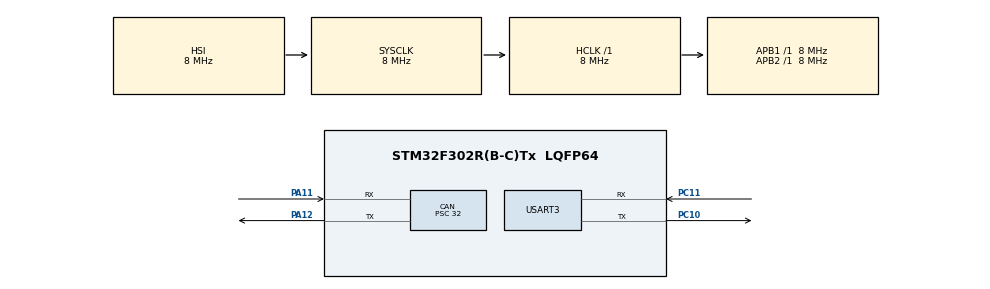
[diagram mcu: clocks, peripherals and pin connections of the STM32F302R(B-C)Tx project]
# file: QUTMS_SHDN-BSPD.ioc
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CAN.CalculateTimeQuantum=4000.0
CAN.Prescaler=32
Mcu.Family=STM32F3
Mcu.Name=STM32F302R(B-C)Tx
Mcu.Package=LQFP64
NVIC.PriorityGroup=NVIC_PRIORITYGROUP_4
PA11.Mode=Master
PA11.Signal=CAN_RX
PA12.Mode=Master
PA12.Signal=CAN_TX
PC10.Mode=Asynchronous
PC10.Signal=USART3_TX
PC11.Mode=Asynchronous
PC11.Signal=USART3_RX
ProjectManager.HeapSize=0x200
ProjectManager.StackSize=0x400
ProjectManager.TargetToolchain=STM32CubeIDE
RCC.AHBFreq_Value=8000000
RCC.APB1Freq_Value=8000000
RCC.APB2Freq_Value=8000000
RCC.CortexFreq_Value=8000000
RCC.HSE_VALUE=8000000
RCC.HSI_VALUE=8000000
RCC.LSE_VALUE=32768
RCC.SYSCLKFreq_VALUE=8000000
USART3.VirtualMode-Asynchronous=VM_ASYNC
board=custom

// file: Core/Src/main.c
/* USER CODE BEGIN Header */
/**
  ******************************************************************************
  * @file           : main.c
  * @brief          : Main program body
  ******************************************************************************
  * @attention
  *
  * <h2><center>&copy; Copyright (c) 2020 STMicroelectronics.
  * All rights reserved.</center></h2>
  *
  * This software component is licensed by ST under BSD 3-Clause license,
  * the "License"; You may not use this file except in compliance with the
  * License. You may obtain a copy of the License at:
  *                        opensource.org/licenses/BSD-3-Clause
  *
  ******************************************************************************
  */
/* USER CODE END Header */
#include "main.h"
#include "can.h"
#include "usart.h"
#include "gpio.h"

/* USER CODE BEGIN PV */
CAN_TxHeaderTypeDef TxHeader;

uint8_t TxData[8];
uint32_t TxMailbox;
/* USER CODE END PV */

void SystemClock_Config(void);

int main(void)
{
  /* USER CODE BEGIN 1 */
	char msg[256];

	TxHeader.ExtId = 0x02;
	TxHeader.IDE = CAN_ID_EXT;
	TxHeader.RTR = CAN_RTR_DATA;
	TxHeader.DLC = 2;
	TxHeader.TransmitGlobalTime = DISABLE;
  /* USER CODE END 1 */

  /* MCU Configuration--------------------------------------------------------*/

  /* Reset of all peripherals, Initializes the Flash interface and the Systick. */
  HAL_Init();

  /* Configure the system clock */
  SystemClock_Config();

  /* Initialize all configured peripherals */
  MX_GPIO_Init();
  MX_CAN_Init();
  MX_USART3_UART_Init();
  /* USER CODE BEGIN 2 */
  if (HAL_CAN_Start(&hcan) != HAL_OK)
  {
	  /* Start Error */
	  sprintf(msg, "can not start.\r\n");
	  HAL_UART_Transmit(&huart3, (uint8_t*) msg, strlen((char*) msg),
			HAL_MAX_DELAY);
	  Error_Handler();
  }

  /* USER CODE END 2 */

  /* Infinite loop */
  while (1)
  {

	// TEST CAN MESSAGE
	TxData[0] = 0;//vol_low;
	TxData[1] = 1;//vol_high;
	// Request transmisison
	if (HAL_CAN_AddTxMessage(&hcan, &TxHeader, TxData, &TxMailbox)
			!= HAL_OK) {
		sprintf(msg, "can error\r\n");
				//sprintf(msg, "result: %d, voltage (%d): %d, pack voltage: %d.\r\n", volRes, cell, voltage, pack_voltage);
				HAL_UART_Transmit(&huart3, (uint8_t*) msg, strlen((char*) msg),
						HAL_MAX_DELAY);
		Error_Handler();
	}

	// TEST LED CODE

  }
}

void SystemClock_Config(void)
{
  RCC_OscInitTypeDef RCC_OscInitStruct = {0};
  RCC_ClkInitTypeDef RCC_ClkInitStruct = {0};
  RCC_PeriphCLKInitTypeDef PeriphClkInit = {0};

  /** Initializes the RCC Oscillators according to the specified parameters
  * in the RCC_OscInitTypeDef structure.
  */
  RCC_OscInitStruct.OscillatorType = RCC_OSCILLATORTYPE_HSI;
  RCC_OscInitStruct.HSIState = RCC_HSI_ON;
  RCC_OscInitStruct.HSICalibrationValue = RCC_HSICALIBRATION_DEFAULT;
  RCC_OscInitStruct.PLL.PLLState = RCC_PLL_NONE;
  if (HAL_RCC_OscConfig(&RCC_OscInitStruct) != HAL_OK)
  {
    Error_Handler();
  }
  /** Initializes the CPU, AHB and APB buses clocks
  */
  RCC_ClkInitStruct.ClockType = RCC_CLOCKTYPE_HCLK|RCC_CLOCKTYPE_SYSCLK
                              |RCC_CLOCKTYPE_PCLK1|RCC_CLOCKTYPE_PCLK2;
  RCC_ClkInitStruct.SYSCLKSource = RCC_SYSCLKSOURCE_HSI;
  RCC_ClkInitStruct.AHBCLKDivider = RCC_SYSCLK_DIV1;
  RCC_ClkInitStruct.APB1CLKDivider = RCC_HCLK_DIV1;
  RCC_ClkInitStruct.APB2CLKDivider = RCC_HCLK_DIV1;

  if (HAL_RCC_ClockConfig(&RCC_ClkInitStruct, FLASH_LATENCY_0) != HAL_OK)
  {
    Error_Handler();
  }
  PeriphClkInit.PeriphClockSelection = RCC_PERIPHCLK_USART3;
  PeriphClkInit.Usart3ClockSelection = RCC_USART3CLKSOURCE_PCLK1;
  if (HAL_RCCEx_PeriphCLKConfig(&PeriphClkInit) != HAL_OK)
  {
    Error_Handler();
  }
}

void Error_Handler(void)
{
}

/************************ (C) COPYRIGHT STMicroelectronics *****END OF FILE****/
